# MKL81Z7 register map
Vendor: Freescale Semiconductor, Inc.; Series: Kinetis_L; File version: 1.6
CPU: CM0PLUS r0p0, little endian, no MPU, no FPU, VTOR, 2 interrupt priority bits
Registers are 32-bit, read-write, reset 0x0 unless marked. A register's access mark holds for its fields unless they carry their own. Offsets are from the block's base; [hi:lo] are bit positions; {n}, {i} and the like mark numbered series; 'fields as' and 'values as' point back to an identical list.

## SIM — System Integration Module
Base 0x40047000; register names take the prefix SIM_
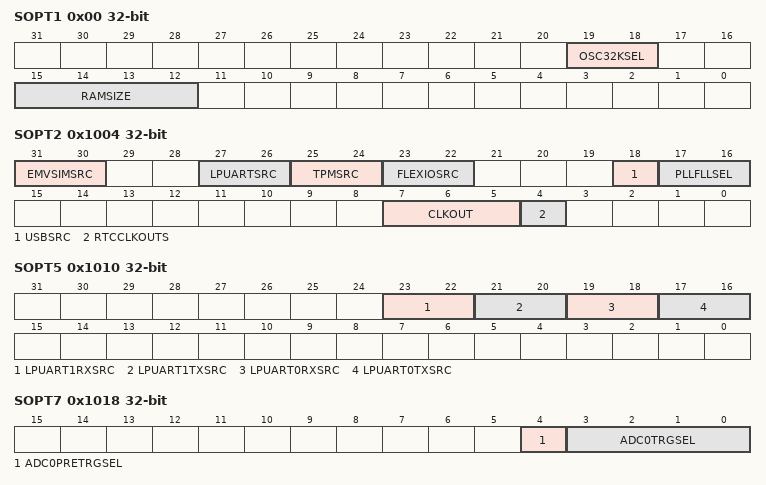
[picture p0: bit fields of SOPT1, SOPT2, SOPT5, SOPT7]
0x00 SOPT1 — System Options Register 1
  [19:18] OSC32KSEL — 32K Oscillator Clock Select
    0=System oscillator (OSC32KCLK); 2=RTC oscillator; 3=LPO 1 kHz
  [15:12] RAMSIZE ro — System RAM Size
    1=8 KB; 3=16 KB; 4=24 KB; 5=32 KB; 6=48 KB; 7=64 KB; 8=96 KB; 9=128 KB; 11=256 KB
0x1004 SOPT2 — System Options Register 2
  [31:30] EMVSIMSRC — EMVSIM Module Clock Source Select
    0=Clock disabled; 1=MCGFLLCLK ,MCGPLLCLK, or IRC48M clock as selected by SOPT2[PLLFLLSEL], and then divided by the PLLFLLCLK fractional divider as configured by SIM_CLKDIV3[PLLFLLFRAC] and SIM_CLKDIV3[PLLFLLDIV]; 2=OSCERCLK clock; 3=MCGIRCLK clock
  [27:26] LPUARTSRC — LPUART clock source select
    values as EMVSIMSRC
  [25:24] TPMSRC — TPM clock source select
    0=Clock disabled; 1=MCGFLLCLK, or MCGPLLCLK, or IRC48M clock as selected by SOPT2[PLLFLLSEL]; 2=OSCERCLK clock; 3=MCGIRCLK clock
  [23:22] FLEXIOSRC — FlexIO Module Clock Source Select
    0=System clock; 1=MCGFLLCLK, or MCGPLLCLK, or IRC48M clock as selected by SOPT2[PLLFLLSEL]; 2=OSCERCLK clock; 3=MCGIRCLK clock
  [18] USBSRC — USB clock source select
    0=External bypass clock (USB_CLKIN); 1=MCGFLLCLK, or MCGPLLCLK, or IRC48M clock as selected by SOPT2[PLLFLLSEL], and then divided by the USB fractional divider as configured by SIM_CLKDIV2[USBFRAC, USBDIV]
  [17:16] PLLFLLSEL — PLL/FLL clock select
    0=MCGFLLCLK clock; 1=MCGPLLCLK clock; 3=IRC48 MHz clock
  [7:5] CLKOUT — CLKOUT select
    2=Flash clock; 3=LPO clock (1 kHz); 4=MCGIRCLK; 5=RTC 32.768kHz clock; 6=OSCERCLK0; 7=IRC 48 MHz clock
  [4] RTCCLKOUTS — RTC clock out select
    0=RTC 1 Hz clock is output on the RTC_CLKOUT pin; 1=RTC 32.768kHz clock is output on the RTC_CLKOUT pin
0x1010 SOPT5 — System Options Register 5
  [23:22] LPUART1RXSRC — LPUART1 receive data source select
    0=LPUART1_RX pin; 1=CMP0
  [21:20] LPUART1TXSRC — LPUART1 transmit data source select
    0=LPUART1_TX pin; 1=LPUART1_TX pin modulated with TPM1 channel 0 output; 2=LPUART1_TX pin modulated with TPM2 channel 0 output
  [19:18] LPUART0RXSRC — LPUART 0 receive data source select
    0=LPUART0_RX pin; 1=CMP0
  [17:16] LPUART0TXSRC — LPUART0 transmit data source select
    0=LPUART0_TX pin; 1=LPUART0_TX pin modulated with TPM1 channel 0 output; 2=LPUART0_TX pin modulated with TPM2 channel 0 output
0x1018 SOPT7 — System Options Register 7
  [4] ADC0PRETRGSEL — ADC0 pretrigger select
    0=Pre-trigger A; 1=Pre-trigger B
  [3:0] ADC0TRGSEL — ADC0 trigger select
    0=External trigger pin input (EXTRG); 1=High speed comparator 0 output; {v}=PIT trigger {v-4} (v=4..7); 8=TPM0 trigger; 9=TPM1 trigger; 10=TPM2 trigger; 11=Low-power timer1 (LPTMR1) trigger; 12=RTC alarm; 13=RTC seconds; 14=Low-power timer (LPTMR) trigger; 15=TPM1 channel 0 (A pretrigger) and channel 1 (B pretrigger)
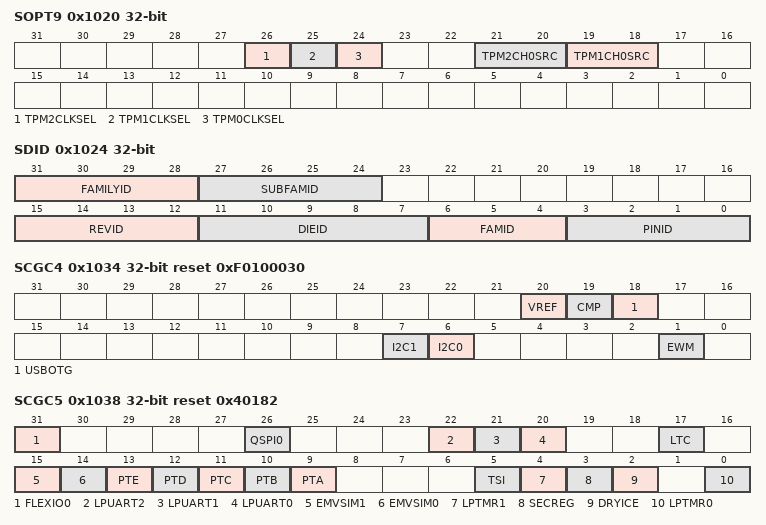
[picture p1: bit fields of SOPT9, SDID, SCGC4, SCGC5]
0x1020 SOPT9 — System Options Register 9
  [26] TPM2CLKSEL — TPM2 External Clock Pin Select
    0=TPM_CLKIN0 pin; 1=TPM_CLKIN1 pin
  [25] TPM1CLKSEL — TPM1 External Clock Pin Select
    0=TPM_CLKIN0 pin; 1=TPM_CLKIN1 pin
  [24] TPM0CLKSEL — TPM0 External Clock Pin Select
    0=TPM_CLKIN0 pin; 1=TPM_CLKIN1 pin
  [21:20] TPM2CH0SRC — TPM2 channel 0 input capture source select
    0=TPM2_CH0 signal; 1=CMP0 output
  [19:18] TPM1CH0SRC — TPM1 channel 0 input capture source select
    0=TPM1_CH0 signal; 1=CMP0 output
0x1024 SDID ro reset not defined — System Device Identification Register
  [31:28] FAMILYID — Kinetis L family ID
    0=KL0x Family; 1=KL1x Family; 2=KL2x Family; 3=KL3x Family); 4=KL4x Family); 6=KL6x Family; 7=KL7x Family; 9=KL8x Family
  [27:24] SUBFAMID — Kinetis Sub-Family ID
    {v}=KLx{v} Subfamily (v=0..9)
  [15:12] REVID — Device Revision Number
  [11:7] DIEID — Device die number
  [6:4] FAMID — Kinetis family ID
  [3:0] PINID — Pincount identification
    5=64-pin; 6=80-pin; 8=100-pin; 9=121-pin; 11=Custom pinout (WLCSP)
0x1034 SCGC4 reset 0xF0100030 — System Clock Gating Control Register 4
  [all] fields
    0=Clock disabled; 1=Clock enabled
  [20] VREF — VREF Clock Gate Control
  [19] CMP — CMP Clock Gate Control
  [18] USBOTG — USB_OTG Clock Gate Control
  [7] I2C1 — I2C1 Clock Gate Control
  [6] I2C0 — I2C0 Clock Gate Control
  [1] EWM — EWM Clock Gate Control
0x1038 SCGC5 reset 0x40182 — System Clock Gating Control Register 5
  [31] FLEXIO0 — FLEXIO0 Clock Gate Control
    0=Clock disabled; 1=Clock enabled
  [26] QSPI0 — QSPI0 Clock Gate Control
    0=Clock disabled; 1=Clock enabled
  [22] LPUART2 — LPUART2 Clock Gate Control
    0=Clock disabled; 1=Clock enabled
  [21] LPUART1 — LPUART1 Clock Gate Control
    0=Clock disabled; 1=Clock enabled
  [20] LPUART0 — LPUART0 Clock Gate Control
    0=Clock disabled; 1=Clock enabled
  [17] LTC — LTC Clock Gate Control
    0=Clock disabled; 1=Clock enabled
  [15] EMVSIM1 — EMVSIM1 Clock Gate Control
    0=Clock disabled; 1=Clock enabled
  [14] EMVSIM0 — EMVSIM0 Clock Gate Control
    0=Clock disabled; 1=Clock enabled
  [13] PTE — PTE Clock Gate Control
    0=Clock disabled; 1=Clock enabled
  [12] PTD — PTD Clock Gate Control
    0=Clock disabled; 1=Clock enabled
  [11] PTC — PTC Clock Gate Control
    0=Clock disabled; 1=Clock enabled
  [10] PTB — PTB Clock Gate Control
    0=Clock disabled; 1=Clock enabled
  [9] PTA — PTA Clock Gate Control
    0=Clock disabled; 1=Clock enabled
  [5] TSI — TSI Access Control
    0=Access disabled; 1=Access enabled
  [4] LPTMR1 — LPTMR1 Clock Gate Control
    0=Clock disabled; 1=Clock enabled
  [3] SECREG — SECREG Clock Gate Control
    0=Clock disabled; 1=Clock enabled
  [2] DRYICE — DRYICE Clock Gate Control
    0=Clock disabled; 1=Clock enabled
  [0] LPTMR0 — LPTMR0 Clock Gate Control
    0=Clock disabled; 1=Clock enabled
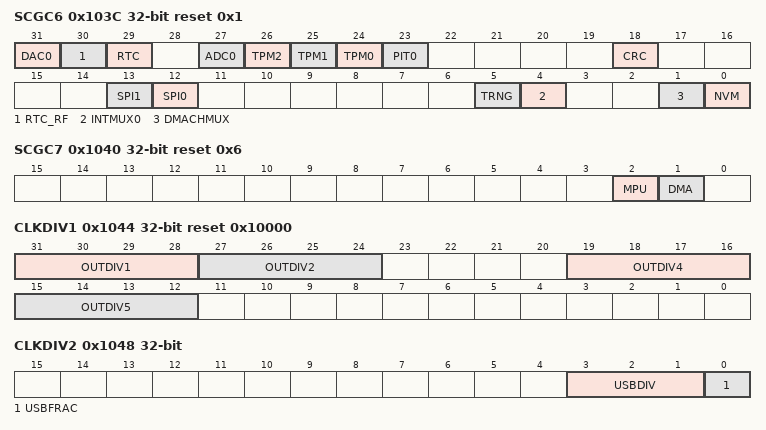
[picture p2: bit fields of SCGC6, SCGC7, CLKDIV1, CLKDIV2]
0x103C SCGC6 reset 0x1 — System Clock Gating Control Register 6
  [all] fields
    0=Clock disabled; 1=Clock enabled
  [31] DAC0 — DAC0 Clock Gate Control
  [30] RTC_RF — RTC_RF Clock Gate Control
  [29] RTC — RTC Clock Gate Control
  [27] ADC0 — ADC0 Clock Gate Control
  [26] TPM2 — TPM2 Clock Gate Control
  [25] TPM1 — TPM1 Clock Gate Control
  [24] TPM0 — TPM0 Clock Gate Control
  [23] PIT0 — PIT0 Clock Gate Control
  [18] CRC — CRC Clock Gate Control
  [13] SPI1 — SPI1 Clock Gate Control
  [12] SPI0 — SPI0 Clock Gate Control
  [5] TRNG — TRNG Clock Gate Control
  [4] INTMUX0 — INTMUX0 Clock Gate Control
  [1] DMACHMUX — DMACHMUX Clock Gate Control
  [0] NVM — NVM Clock Gate Control
0x1040 SCGC7 reset 0x6 — System Clock Gating Control Register 7
  [2] MPU — MPU Clock Gate Control
    0=Clock disabled; 1=Clock enabled
  [1] DMA — DMA Clock Gate Control
    0=Clock disabled; 1=Clock enabled
0x1044 CLKDIV1 reset 0x10000 — System Clock Divider Register 1
  [31:28] OUTDIV1 — Clock 1 output divider value
    {v}=Divide-by-{v+1} (v=0..15)
  [27:24] OUTDIV2 — Clock 2 output divider value
    {v}=Divide-by-{v+1} (v=0..15)
  [19:16] OUTDIV4 — Clock 4 output divider value
    {v}=Divide-by-{v+1} (v=0..15)
  [15:12] OUTDIV5 — Clock 5 output divider value
    0=Divide-by-1; 1=Divide-by-2
0x1048 CLKDIV2 — System Clock Divider Register 2
  [3:1] USBDIV — USB clock divider divisor
  [0] USBFRAC — USB clock divider fraction
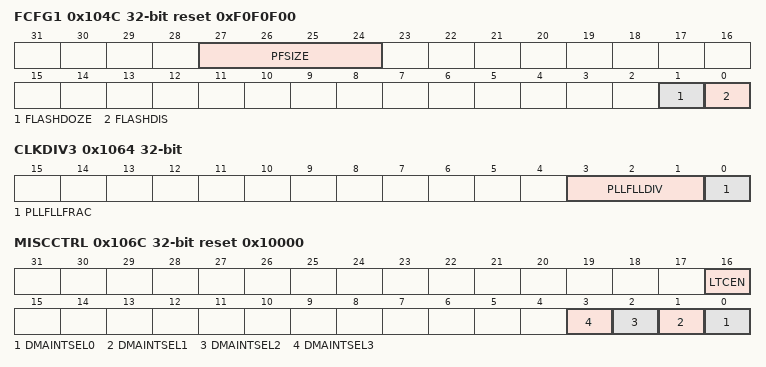
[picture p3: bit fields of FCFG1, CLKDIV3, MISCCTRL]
0x104C FCFG1 reset 0xF0F0F00 — Flash Configuration Register 1
  [27:24] PFSIZE ro — Program flash size
    3=32 KB of program flash memory; 5=64 KB of program flash memory; 7=128 KB of program flash memory; 9=256 KB of program flash memory; 11=512 KB of program flash memory; 13=1024 KB of program flash memory; 15=128 KB of program flash memory
  [1] FLASHDOZE
    0=Flash remains enabled during Wait mode; 1=Flash is disabled for the duration of Wait mode
  [0] FLASHDIS — Flash Disable
    0=Flash is enabled; 1=Flash is disabled
0x1050 FCFG2 ro reset 0x800000 — Flash Configuration Register 2
  [30:24] MAXADDR0 — Max address block 0
0x1054 UIDH ro reset not defined — Unique Identification Register High
  [31:0] UID — Unique Identification
0x1058 UIDMH ro reset not defined — Unique Identification Register Mid-High
  [31:0] UID — Unique Identification
0x105C UIDML ro reset not defined — Unique Identification Register Mid Low
  [31:0] UID — Unique Identification
0x1060 UIDL ro reset not defined — Unique Identification Register Low
  [31:0] UID — Unique Identification
0x1064 CLKDIV3 — System Clock Divider Register 3
  [3:1] PLLFLLDIV — PLLFLL clock divider divisor
  [0] PLLFLLFRAC — PLLFLL clock divider fraction
0x106C MISCCTRL reset 0x10000 — Misc Control Register
  [16] LTCEN ro — LTC Status
    0=LTC is not available; 1=LTC is available
  [n] DMAINTSEL{n} (n=0..3) — DMA Channel Interrupts Select {n}
    0=DMA0 channel {n+4} is not available in vector {n+16}; 1=DMA0 channel {n+4} is available in vector {n+16}
{0x1090+4i} SECKEY{i} ro reset not defined (i=0..3) — Secure Key Register {i}
  [31:0] SECKEY — Secure Key 31:0
